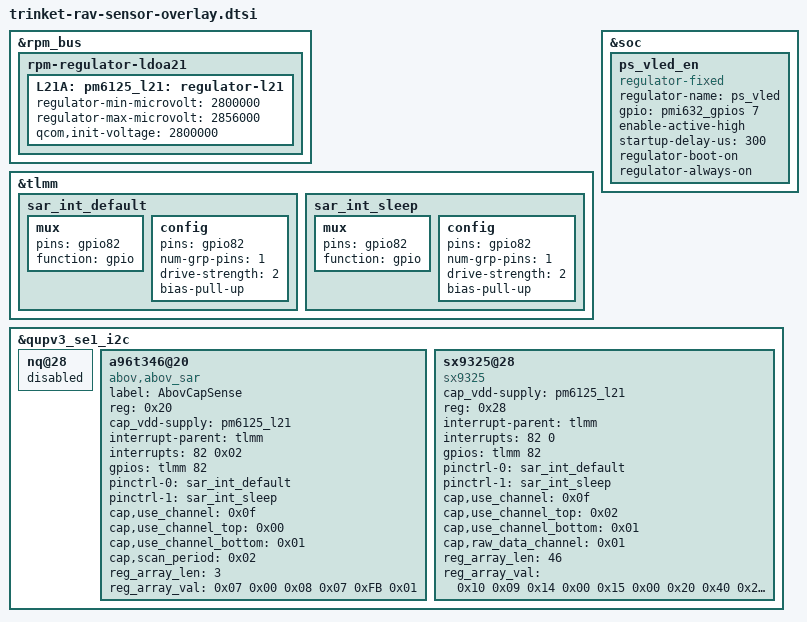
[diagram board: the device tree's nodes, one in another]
/* Copyright (c) 2018, The Linux Foundation. All rights reserved.
 *
 * This program is free software; you can redistribute it and/or modify
 * it under the terms of the GNU General Public License version 2 and
 * only version 2 as published by the Free Software Foundation.
 *
 * This program is distributed in the hope that it will be useful,
 * but WITHOUT ANY WARRANTY; without even the implied warranty of
 * MERCHANTABILITY or FITNESS FOR A PARTICULAR PURPOSE.  See the
 * GNU General Public License for more details.
 */

&rpm_bus {
	rpm-regulator-ldoa21 {
		status = "okay";
		L21A: pm6125_l21: regulator-l21 {
			regulator-min-microvolt = <2800000>;
			regulator-max-microvolt = <2856000>;
			qcom,init-voltage = <2800000>;
			status = "okay";
		};
	};
};

&tlmm {
	sar_int_default: sar_int_default {
			mux {
				pins = "gpio82";
				function =  "gpio";
			};
			config {
				pins = "gpio82";
				num-grp-pins = <1>;
				drive-strength = <2>;
				bias-pull-up;
			};
	};

	sar_int_sleep: sar_int_sleep {
			mux {
				pins = "gpio82";
				function =  "gpio";
			};
			config {
				pins = "gpio82";
				num-grp-pins = <1>;
				drive-strength = <2>;
				bias-pull-up;
			};
	};
};

&soc {
	ps_vled_en: ps_vled_en {
		compatible = "regulator-fixed";
		regulator-name = "ps_vled";
		gpio = <&pmi632_gpios 7 0>;
		enable-active-high;
		startup-delay-us = <300>;
		regulator-boot-on;
		regulator-always-on;
	};
};

&qupv3_se1_i2c { /* BLSP2 QUP1 (NFC) */
	nq@28 {
		status = "disabled";
	};
};

&qupv3_se1_i2c {
	status = "ok";
	a96t346@20 {
		status = "ok";
		label = "AbovCapSense";
		compatible = "abov,abov_sar";
		reg = <0x20>;
		cap_vdd-supply = <&pm6125_l21>;
		interrupt-parent = <&tlmm>;
		interrupts = <82 0x02>;
		interrupt-names = "abov_irq";
		gpios = <&tlmm 82 0x02>;
		pinctrl-names = "default","sleep";
		pinctrl-0 = <&sar_int_default>;
		pinctrl-1 = <&sar_int_sleep>;
		cap,use_channel = <0x0f>;
		cap,use_channel_top = <0x00>;
		cap,use_channel_bottom = <0x01>;
		//cap,use_channel_middle = <0x02>;
		cap,scan_period = <0x02>;
		reg_array_len = <3>;
		reg_array_val = <0x07 0x00 0x08 0x07 0xFB 0x01>;
	};

	sx9325@28 {
        	compatible = "sx9325";
		cap_vdd-supply = <&pm6125_l21>;
        	reg = <0x28>;
        	interrupt-parent = <&tlmm>;
        	interrupts = <82 0>;
        	gpios = <&tlmm 82 0x00>;
        	pinctrl-names = "default","sleep";
       	 	pinctrl-0 = <&sar_int_default>;
		pinctrl-1 = <&sar_int_sleep>;
		cap,use_channel = <0x0f>;
		cap,use_channel_top = <0x02>;
		cap,use_channel_bottom = <0x01>;
		cap,raw_data_channel = <0x01>;
        	reg_array_len = <46>; /* total registers number to initialize*/
        	reg_array_val = < 0x10 0x09
                                0x14 0x00
                                0x15 0x00
                                0x20 0x40
                                0x21 0x10
                                0x22 0x00
                                0x23 0x01
                                0x24 0x87
                                0x25 0x00
                                0x26 0x00
                                0x27 0x87
                                0x28 0x3D /*PH0 - CS0 input*/
                                0x29 0x1F /*PH1 - CS1 input*/
                                0x2A 0x37 /*PH2 - CS2-input,others Gnd*/
                                0x2B 0x37
                                0x2C 0x12
                                0x2D 0x0F
                                0x30 0x0B
                                0x31 0x0B
                                0x32 0x20
                                0x33 0x60
                                0x34 0x0C
                                0x35 0x00
                                0x36 0x20
                                0x37 0x20
                                0x40 0x00
                                0x41 0x00
                                0x42 0x18
                                0x43 0x20
                                0x44 0x00
                                0x45 0x05
                                0x46 0x00
                                0x47 0x00
                                0x48 0x00
                                0x49 0x00
                                0x4A 0x11 /*Body threshold setting*/
                                0x4B 0x00
                                0x4C 0x00
                                0x50 0x00
                                0x51 0x00
                                0x52 0x00
                                0x05 0x74 /*enable PROG2*/
                                0x06 0x00
                                0x07 0x80
                                0x08 0x00
                                0x11 0x27>;
        };
};
